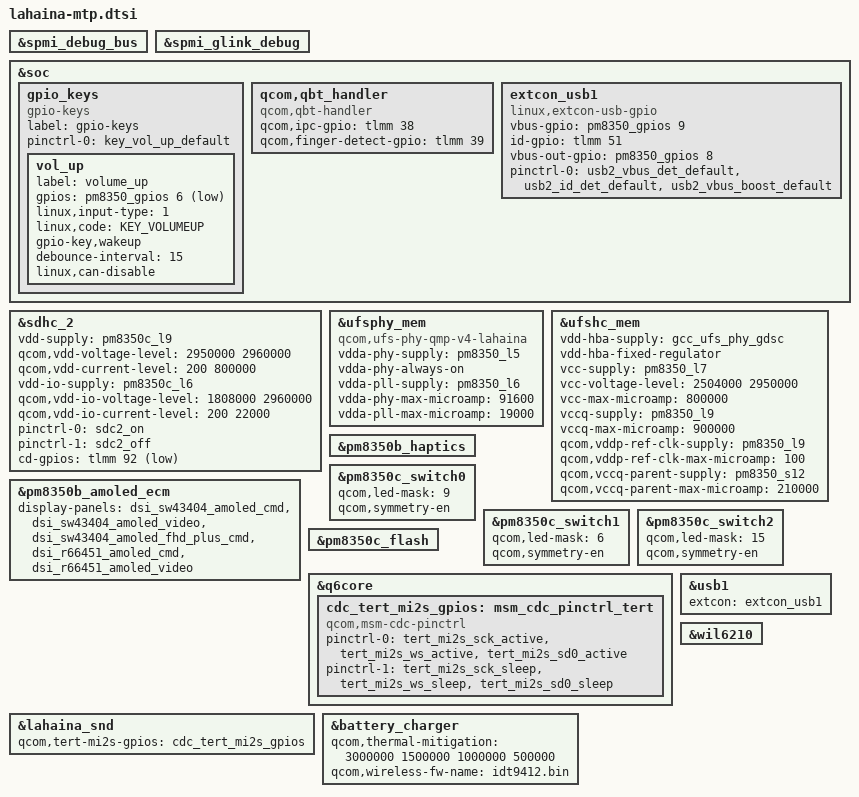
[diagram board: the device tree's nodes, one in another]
#include <dt-bindings/gpio/gpio.h>
#include <dt-bindings/input/input.h>

#include "lahaina-pmic-overlay.dtsi"
#include "lahaina-audio-overlay.dtsi"
#include "display/lahaina-sde-display-mtp.dtsi"
#include "lahaina-thermal-overlay.dtsi"

&spmi_debug_bus {
	status = "ok";
};

&spmi_glink_debug {
	status = "ok";
};

&soc {
	gpio_keys {
		compatible = "gpio-keys";
		label = "gpio-keys";

		pinctrl-names = "default";
		pinctrl-0 = <&key_vol_up_default>;

		vol_up {
			label = "volume_up";
			gpios = <&pm8350_gpios 6 GPIO_ACTIVE_LOW>;
			linux,input-type = <1>;
			linux,code = <KEY_VOLUMEUP>;
			gpio-key,wakeup;
			debounce-interval = <15>;
			linux,can-disable;
		};
	};

	qcom,qbt_handler {
		compatible = "qcom,qbt-handler";
		qcom,ipc-gpio = <&tlmm 38 0>;
		qcom,finger-detect-gpio = <&tlmm 39 0>;
	};

	extcon_usb1: extcon_usb1 {
		compatible = "linux,extcon-usb-gpio";
		vbus-gpio =  <&pm8350_gpios 9 GPIO_ACTIVE_HIGH>;
		id-gpio = <&tlmm 51 GPIO_ACTIVE_HIGH>;
		vbus-out-gpio = <&pm8350_gpios 8 GPIO_ACTIVE_HIGH>;

		pinctrl-names = "default";
		pinctrl-0 = <&usb2_vbus_det_default
			     &usb2_id_det_default
			     &usb2_vbus_boost_default>;
	};
};

&sdhc_2 {
	vdd-supply = <&pm8350c_l9>;
	qcom,vdd-voltage-level = <2950000 2960000>;
	qcom,vdd-current-level = <200 800000>;

	vdd-io-supply = <&pm8350c_l6>;
	qcom,vdd-io-voltage-level = <1808000 2960000>;
	qcom,vdd-io-current-level = <200 22000>;

	pinctrl-names = "default", "sleep";
	pinctrl-0 = <&sdc2_on>;
	pinctrl-1 = <&sdc2_off>;

	cd-gpios = <&tlmm 92 GPIO_ACTIVE_LOW>;

	status = "ok";
};


&ufsphy_mem {
	compatible = "qcom,ufs-phy-qmp-v4-lahaina";

	vdda-phy-supply = <&pm8350_l5>;
	vdda-phy-always-on;
	vdda-pll-supply = <&pm8350_l6>;
	vdda-phy-max-microamp = <91600>;
	vdda-pll-max-microamp = <19000>;

	status = "ok";
};

&ufshc_mem {
	vdd-hba-supply = <&gcc_ufs_phy_gdsc>;
	vdd-hba-fixed-regulator;

	vcc-supply = <&pm8350_l7>;
	vcc-voltage-level = <2504000 2950000>;
	vcc-max-microamp = <800000>;

	vccq-supply = <&pm8350_l9>;
	vccq-max-microamp = <900000>;

	qcom,vddp-ref-clk-supply = <&pm8350_l9>;
	qcom,vddp-ref-clk-max-microamp = <100>;

	qcom,vccq-parent-supply = <&pm8350_s12>;
	qcom,vccq-parent-max-microamp = <210000>;

	status = "ok";
};

&pm8350b_haptics {
	status = "ok";
};

&pm8350b_amoled_ecm {
	display-panels = <&dsi_sw43404_amoled_cmd
			  &dsi_sw43404_amoled_video
			  &dsi_sw43404_amoled_fhd_plus_cmd
			  &dsi_r66451_amoled_cmd
			  &dsi_r66451_amoled_video>;
};

&pm8350c_switch0 {
	qcom,led-mask = <9>; /* Channels 1 & 4 */
	qcom,symmetry-en;
};

&pm8350c_switch1 {
	qcom,led-mask = <6>; /* Channels 2 & 3 */
	qcom,symmetry-en;
};

&pm8350c_switch2 {
	qcom,led-mask = <15>; /* All Channels */
	qcom,symmetry-en;
};

&pm8350c_flash {
	status = "ok";
};

&q6core {
	cdc_tert_mi2s_gpios: msm_cdc_pinctrl_tert {
		compatible = "qcom,msm-cdc-pinctrl";
		pinctrl-names = "aud_active", "aud_sleep";
		pinctrl-0 = <&tert_mi2s_sck_active &tert_mi2s_ws_active
				&tert_mi2s_sd0_active>;
		pinctrl-1 = <&tert_mi2s_sck_sleep &tert_mi2s_ws_sleep
				&tert_mi2s_sd0_sleep>;
		#gpio-cells = <0>;
	};
};

&lahaina_snd {
	qcom,tert-mi2s-gpios = <&cdc_tert_mi2s_gpios>;
};

&usb1 {
	extcon = <&extcon_usb1>;
};

&battery_charger {
	qcom,thermal-mitigation = <3000000 1500000 1000000 500000>;
	qcom,wireless-fw-name = "idt9412.bin";
};

&wil6210 {
	status = "ok";
};

#include "camera/lahaina-camera-sensor-mtp.dtsi"
